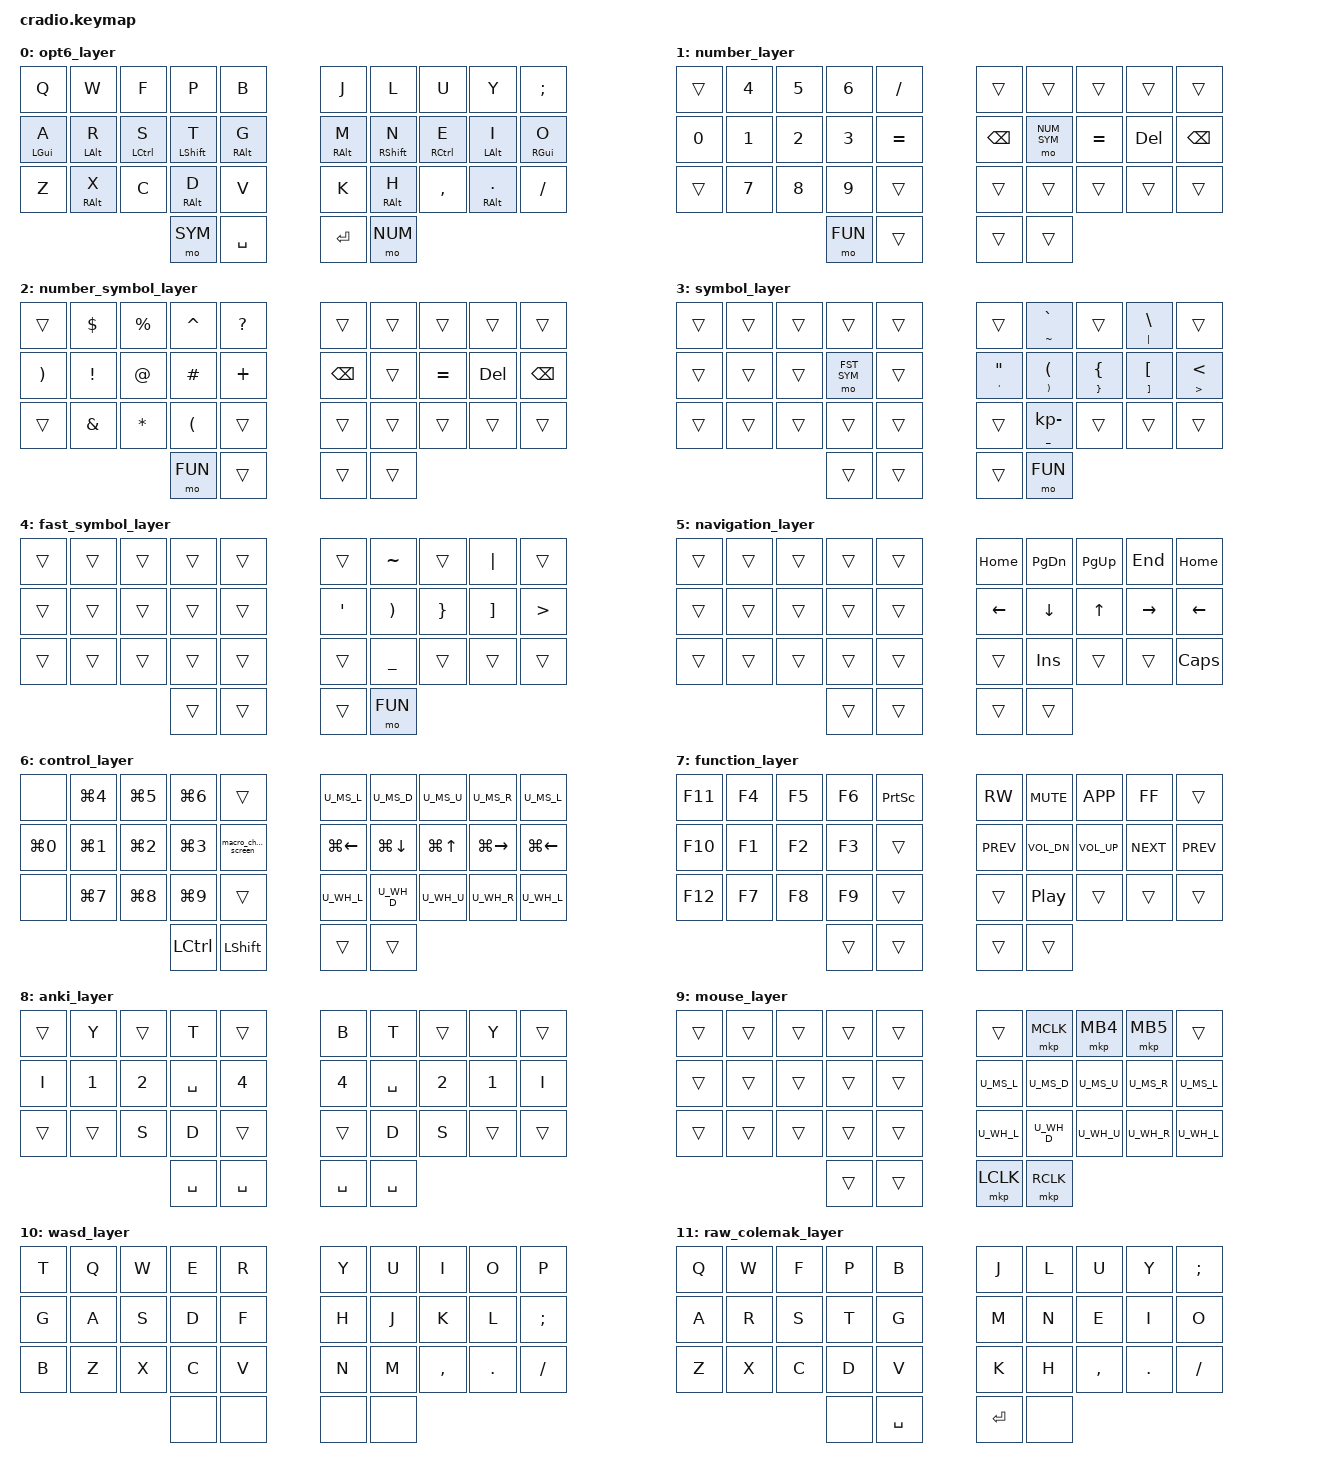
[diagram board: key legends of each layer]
/*
 * Copyright (c) 2020 The ZMK Contributors
 *
 * SPDX-License-Identifier: MIT
 */


// KEY NUMBERS
    // |    0    |    1    |    2    |    3    |     4   |        |     5   |     6   |    7    |    8    |    9    |
    // |   10    |   11    |   12    |   13    |    14   |        |    15   |    16   |   17    |   18    |   19    |
    // |   20    |   21    |   22    |   23    |    24   |        |    25   |    26   |   27    |   28    |   29    |
    //                               |   30    |    31   |        |    32   |    33   |

#include <behaviors.dtsi>
#include <dt-bindings/zmk/keys.h>
#include <dt-bindings/zmk/bt.h>
#include <dt-bindings/zmk/mouse.h>

// Layer definitions
#define DEF 0
#define NUM 1
#define NUM_SYM 2
#define SYM 3
#define FST_SYM 4
#define NAV 5
#define CTR 6
#define FUN 7
#define ANKI 8
#define MOUSELAYER 9
#define WASD 10
#define RAW_COLEMAK 11

// Combo timeout
#define COMBO_TIMEOUT 40

// Combo keys
#define COMBO_ESC 2 3
#define COMBO_TAB 13 14
#define COMBO_NAV 30 31
#define COMBO_CTR 32 33
#define COMBO_ANKI 25 26 27
#define COMBO_WASD 2 11 13
#define COMBO_RAW_COLEMAK 1 10 23
#define COMBO_MOUSELAYER 10 20
//#define COMBO_BT_CLR 0 10 20 9 19 29
//#define COMBO_BT_PRV 0 10 20 15
//#define COMBO_BT_NXT 0 10 20 18
#define COMBO_BT_CLR 0 4
#define COMBO_BT_PRV 0 14
#define COMBO_BT_NXT 0 24
#define COMBO_CUT 21 23
#define COMBO_COPY 21 22
#define COMBO_PASTE 22 23
#define COMBO_UNDO 1 2
#define COMBO_REDO 1 3

#define COMBO_ANKI_L 22 23 24
#define COMBO_ESC_R 7 8
#define COMBO_TAB_R 15 16
#define COMBO_CUT_R 26 28
#define COMBO_COPY_R 26 27
#define COMBO_PASTE_R 27 28
#define COMBO_UNDO_R 6 7
#define COMBO_REDO_R 6 8

#include "mouse.dtsi"

// Thumb keys
#define LEFT_THUMB_KEYS 30 31
#define RIGHT_THUMB_KEYS 32 33

// Halve keys
#define LEFT_SIDE_KEYS 0 1 2 3 4 10 11 12 13 14 20 21 22 23 24 LEFT_THUMB_KEYS
#define RIGHT_SIDE_KEYS 5 6 7 8 9 15 16 17 18 19 25 26 27 28 29 RIGHT_THUMB_KEYS


/ {
    behaviors {
        dk: dual_key {
            compatible = "zmk,behavior-hold-tap";
            label = "DUAL_KEY";
            #binding-cells = <2>;
            flavor = "tap-preferred";
            tapping-term-ms = <200>;
            quick-tap-ms = <0>;
            bindings = <&kp>, <&kp>;
        };

        lhm: left_homerow_mods {
            compatible = "zmk,behavior-hold-tap";
            #binding-cells = <2>;
            flavor = "balanced";
            tapping-term-ms = <250>;
            quick-tap-ms = <150>;
            hold-trigger-key-positions = <RIGHT_SIDE_KEYS LEFT_THUMB_KEYS>;
            hold-trigger-on-release;
            bindings = <&kp>, <&kp>;
        };

        rhm: right_homerow_mods {
            compatible = "zmk,behavior-hold-tap";
            #binding-cells = <2>;
            flavor = "balanced";
            tapping-term-ms = <250>;
            quick-tap-ms = <150>;
            hold-trigger-key-positions = <LEFT_SIDE_KEYS RIGHT_THUMB_KEYS>;
            hold-trigger-on-release;
            bindings = <&kp>, <&kp>;
        };
    };

    macros {
        macro_copy: macro_copy {
            label = "macro_copy";
            compatible = "zmk,behavior-macro";
            #binding-cells = <0>;
            bindings
                = <&macro_press &kp LCTRL>
                , <&macro_tap &kp C>
                , <&macro_release &kp LCTRL>
                ;
        };
        macro_paste: macro_paste {
            label = "macro_paste";
            compatible = "zmk,behavior-macro";
            #binding-cells = <0>;
            bindings
                = <&macro_press &kp LCTRL>
                , <&macro_tap &kp V>
                , <&macro_release &kp LCTRL>
                ;
        };
        macro_cut: macro_cut {
            label = "macro_cut";
            compatible = "zmk,behavior-macro";
            #binding-cells = <0>;
            bindings
                = <&macro_press &kp LCTRL>
                , <&macro_tap &kp X>
                , <&macro_release &kp LCTRL>
                ;
        };

        macro_undo: macro_undo {
            label = "macro_undo";
            compatible = "zmk,behavior-macro";
            #binding-cells = <0>;
            bindings
                = <&macro_press &kp LCTRL>
                , <&macro_tap &kp Z>
                , <&macro_release &kp LCTRL>
                ;
        };
        macro_redo: macro_redo {
            label = "macro_redo";
            compatible = "zmk,behavior-macro";
            #binding-cells = <0>;
            bindings
                = <&macro_press &kp LCTRL>
                , <&macro_tap &kp Y>
                , <&macro_release &kp LCTRL>
                ;
        };
        macro_change_screen: macro_change_screen {
            label = "macro_change_screen";
            compatible = "zmk,behavior-macro";
            #binding-cells = <0>;
            bindings
                = <&macro_press &kp LCTRL>
                , <&macro_press &kp LSHIFT>
                , <&macro_tap &kp LG(RIGHT)>
                , <&macro_release &kp LSHIFT>
                , <&macro_release &kp LCTRL>
                ;
        };
    };

    combos {
        compatible = "zmk,combos";

        combo_esc {
            timeout-ms = <COMBO_TIMEOUT>;
            key-positions = <COMBO_ESC>;
            bindings = <&kp ESC>;
        };
        
        combo_tab {
            timeout-ms = <COMBO_TIMEOUT>;
            key-positions = <COMBO_TAB>;
            bindings = <&kp TAB>;
        };

        combo_esc_r {
            timeout-ms = <COMBO_TIMEOUT>;
            key-positions = <COMBO_ESC_R>;
            bindings = <&kp ESC>;
        };
        
        combo_tab_r {
            timeout-ms = <COMBO_TIMEOUT>;
            key-positions = <COMBO_TAB_R>;
            bindings = <&kp TAB>;
        };

        combo_nav{
            timeout-ms = <COMBO_TIMEOUT>;
            key-positions = <COMBO_NAV>;
            bindings = <&mo NAV>;
        };

        combo_ctr{
            timeout-ms = <COMBO_TIMEOUT>;
            key-positions = <COMBO_CTR>;
            bindings = <&mo CTR>;
        };

        combo_anki{
            timeout-ms = <COMBO_TIMEOUT>;
            key-positions = <COMBO_ANKI>;
            bindings = <&tog ANKI>;
        };
        combo_mouselayer{
            timeout-ms = <COMBO_TIMEOUT>;
            key-positions = <COMBO_MOUSELAYER>;
            bindings = <&tog MOUSELAYER>;
        };
        combo_wasd{
            timeout-ms = <COMBO_TIMEOUT>;
            key-positions = <COMBO_WASD>;
            bindings = <&tog WASD>;
        };
        combo_raw_colemak{
            timeout-ms = <COMBO_TIMEOUT>;
            key-positions = <COMBO_RAW_COLEMAK>;
            bindings = <&tog RAW_COLEMAK>;
        };

        combo_anki_l{
            timeout-ms = <COMBO_TIMEOUT>;
            key-positions = <COMBO_ANKI_L>;
            bindings = <&tog ANKI>;
        };

        combo_bt_clr{
            timeout-ms = <COMBO_TIMEOUT>;
            key-positions = <COMBO_BT_CLR>;
            bindings = <&bt BT_CLR>;
        };

        combo_bt_prv{
            timeout-ms = <COMBO_TIMEOUT>;
            key-positions = <COMBO_BT_PRV>;
            bindings = <&bt BT_PRV>;
        };

        combo_bt_nxt{
            timeout-ms = <COMBO_TIMEOUT>;
            key-positions = <COMBO_BT_NXT>;
            bindings = <&bt BT_NXT>;
        };

        combo_cut {
            timeout-ms = <COMBO_TIMEOUT>;
            key-positions = <COMBO_CUT>;
            bindings = <&macro_cut>;
        };
        combo_copy {
            timeout-ms = <COMBO_TIMEOUT>;
            key-positions = <COMBO_COPY>;
            bindings = <&macro_copy>;
        };
        combo_paste {
            timeout-ms = <COMBO_TIMEOUT>;
            key-positions = <COMBO_PASTE>;
            bindings = <&macro_paste>;
        };

        combo_undo {
            timeout-ms = <COMBO_TIMEOUT>;
            key-positions = <COMBO_UNDO>;
            bindings = <&macro_undo>;
        };
        combo_redo {
            timeout-ms = <COMBO_TIMEOUT>;
            key-positions = <COMBO_REDO>;
            bindings = <&macro_redo>;
        };

        
        combo_cut_r {
            timeout-ms = <COMBO_TIMEOUT>;
            key-positions = <COMBO_CUT_R>;
            bindings = <&macro_cut>;
        };
        combo_copy_r {
            timeout-ms = <COMBO_TIMEOUT>;
            key-positions = <COMBO_COPY_R>;
            bindings = <&macro_copy>;
        };
        combo_paste_r {
            timeout-ms = <COMBO_TIMEOUT>;
            key-positions = <COMBO_PASTE_R>;
            bindings = <&macro_paste>;
        };

        combo_undo_r {
            timeout-ms = <COMBO_TIMEOUT>;
            key-positions = <COMBO_UNDO_R>;
            bindings = <&macro_undo>;
        };
        combo_redo_r {
            timeout-ms = <COMBO_TIMEOUT>;
            key-positions = <COMBO_REDO_R>;
            bindings = <&macro_redo>;
        };
    };

    keymap {
        compatible = "zmk,keymap";
            

    // colemakDH (default layer)
        // |    Q    |    W    |    F    |    P    |    B    |        |    J    |    L    |    U    |    Y    |    ;    |
        // |    A    |    R    |    S    |    T    |    G    |        |    M    |    N    |    E    |    I    |    O    |
        // |    Z    |    X    |    C    |    D    |    V    |        |    K    |    H    |    ,    |    .    |    /    |
        //                               |   SYM   |   SPC   |        |  ENTER  |   NUM   |

        opt6_layer {
            bindings = <
            &kp Q       &kp W       &kp F           &kp P           &kp B              &kp J       &kp L           &kp U           &kp Y             &kp SEMI
            &lhm LGUI A &lhm LALT R &lhm LCTRL S    &lhm LSHIFT T   &lhm RALT G        &rhm RALT M &rhm RSHIFT N   &rhm RCTRL E    &rhm LALT I       &rhm RGUI O
            &kp Z       &lhm RALT X &kp C           &lhm RALT D     &kp V              &kp K       &rhm RALT H     &kp COMMA       &rhm RALT DOT     &kp SLASH
                                                    &mo SYM         &kp SPC            &kp ENTER   &mo NUM
            >;
        };


    // number_layer
        // |         |    4    |    5    |    6    |    /    |        |         |         |         |         |         |
        // |    0    |    1    |    2    |    3    |    =    |        |  BSPC   | NUM_SYM |    =    |   DEL   |   BSPC  |
        // |         |    7    |    8    |    9    |         |        |         |         |         |         |         |
        //                               |   FUN   |   SPC   |        |  ENTER  | PRESSED |

        number_layer {
            bindings = <
            &trans      &kp NUM_4   &kp NUM_5   &kp NUM_6   &kp SLASH          &trans      &trans      &trans      &trans      &trans
            &kp NUM_0   &kp NUM_1   &kp NUM_2   &kp NUM_3   &kp EQUAL          &kp BSPC    &mo NUM_SYM &kp EQUAL   &kp DEL     &kp BSPC
            &trans      &kp NUM_7   &kp NUM_8   &kp NUM_9   &trans             &trans      &trans      &trans      &trans      &trans
                                                &mo FUN     &trans             &trans      &trans
            >;
        };


    // number_symbol_layer
        // |         |    $    |    %    |    ^    |    ?    |        |         |         |         |         |         |
        // |    )    |    !    |    @    |    #    |    +    |        |  BSPC   | PRESSED |    =    |   DEL   |   BSPC  |
        // |         |    &    |    *    |    (    |    _    |        |         |         |         |         |         |
        //                               |   FUN   |   SPC   |        |  ENTER  | PRESSED |

        number_symbol_layer {
            bindings = <
            &trans      &kp DOLLAR      &kp PERCENT         &kp CARET        &kp QMARK          &trans      &trans      &trans      &trans      &trans
            &kp RPAR    &kp EXCL        &kp AT              &kp HASH         &kp PLUS           &kp BSPC    &trans      &kp EQUAL   &kp DEL     &kp BSPC
            &trans      &kp AMPS        &kp ASTRK           &kp LPAR         &trans             &trans      &trans      &trans      &trans      &trans
                                        &mo FUN             &trans           &trans             &trans
            >;
        };


    // symbol_layer
        // |         |         |         |         |         |        |         |   ` ~   |         |   \ |   |         |
        // |         |         |         | FST_SYM |         |        |   " '   |   ( )   |   { }   |   [ ]   |   < >   |
        // |         |         |         |         |         |        |         |   - _   |         |         |         |
        //                               | PRESSED |   SPC   |        |  ENTER  |   FUN   | 

        symbol_layer {
            bindings = <
            &trans  &trans  &trans  &trans      &trans          &trans         &dk TILDE GRAVE     &trans          &dk PIPE BSLH   &trans
            &trans  &trans  &trans  &mo FST_SYM &trans          &dk APOS DQT   &dk RPAR LPAR       &dk RBRC LBRC   &dk RBKT LBKT   &dk GT LT
            &trans  &trans  &trans  &trans      &trans          &trans         &dk UNDER KP_MINUS  &trans          &trans          &trans
                                    &trans      &trans          &trans         &mo FUN
            >;
        };


    // fast_symbol_layer
        // |         |         |         |         |         |        |         |    ~    |         |    |    |         |
        // |         |         |         |         |         |        |    '    |    )    |    }    |    ]    |    >    |
        // |         |         |         |         |         |        |         |    _    |         |         |         |
        //                               | PRESSED |   SPC   |        |  ENTER  |   FUN   | 

        fast_symbol_layer {
            bindings = <
            &trans  &trans  &trans  &trans  &trans          &trans          &kp TILDE       &trans          &kp PIPE        &trans
            &trans  &trans  &trans  &trans  &trans          &kp APOS        &kp RPAR        &kp RBRC        &kp RBKT        &kp GT
            &trans  &trans  &trans  &trans  &trans          &trans          &kp UNDER       &trans          &trans          &trans
                                    &trans  &trans          &trans          &mo FUN
            >;
        };


    // navigation_layer
        // |         |         |         |         |         |        |   Home  | Pg down |  Pg up  |   End   |   Home  |
        // |         |         |         |         |         |        |    ←    |    ↓    |    ↑    |    →   |    ←   |
        // |         |         |         |         |         |        |         |   INS   |         |         |   Caps  |
        //                               |  COMBO  |  COMBO  |        |         |         |

        navigation_layer {
            bindings = <
            &trans  &trans  &trans  &trans  &trans          &kp HOME    &kp PG_DN   &kp PG_UP   &kp END     &kp HOME
            &trans  &trans  &trans  &trans  &trans          &kp LEFT    &kp DOWN    &kp UP      &kp RIGHT   &kp LEFT
            &trans  &trans  &trans  &trans  &trans          &trans      &kp INSERT  &trans      &trans      &kp CAPS
                                    &trans  &trans          &trans      &trans
            >;
        };


    // control_layer
        // Everything is gui modified
        // |         |    4    |    5    |    6    |         |        |    ←   |     ↓    |    ↑   |    →    |    ←    | // mouse
        // |    0    |    1    |    2    |    3    |         |        |    ←   |     ↓    |    ↑   |    →    |    ←    | // gui
        // |         |    7    |    8    |    9    |         |        |    ←   |     ↓    |    ↑   |    →    |    ←    | // wheel
        //                               |  SHIFT  |  lCtrl  |        |  COMBO  |   COMBO  |

        control_layer {
            bindings = <
            &none           &kp LG(NUM_4)   &kp LG(NUM_5)       &kp LG(NUM_6)       &trans                      U_MS_L            U_MS_D                U_MS_U          U_MS_R          U_MS_L
            &kp LG(NUM_0)   &kp LG(NUM_1)   &kp LG(NUM_2)       &kp LG(NUM_3)       &macro_change_screen        &kp LG(LEFT)      &kp LG(DOWN)          &kp LG(UP)      &kp LG(RIGHT)   &kp LG(LEFT)
            &none           &kp LG(NUM_7)   &kp LG(NUM_8)       &kp LG(NUM_9)       &trans                      U_WH_L            U_WH_D                U_WH_U          U_WH_R          U_WH_L
                                                                &kp LCTRL           &kp LSHIFT                  &trans            &trans
            >;
        };


    // function_layer
        // |   F11   |    F4   |    F5   |    F6   |  PrtScn |        |   C_RW  |  vol 1/0 |  K_APP |  C_FF   |         |
        // |   F10   |    F1   |    F2   |    F3   |         |        | med prev|   vol-   |   vol+ | med next| med prev|
        // |   F12   |    F7   |    F8   |    F9   |         |        |         | media p/p|        |         |         |
        //                               | PRESSED |         |        |         |  PRESSED |

        function_layer {
            bindings = <
            &kp F11 &kp F4  &kp F5  &kp F6  &kp PSCRN              &kp C_RW    &kp C_MUTE        &kp K_APP       &kp C_FF    &trans
            &kp F10 &kp F1  &kp F2  &kp F3  &trans                 &kp C_PREV  &kp C_VOL_DN      &kp C_VOL_UP    &kp C_NEXT  &kp C_PREV
            &kp F12 &kp F7  &kp F8  &kp F9  &trans                 &trans      &kp C_PLAY_PAUSE  &trans          &trans      &trans
                                    &trans  &trans                 &trans      &trans
            >;
        };


    // anki_layer
        // |&tog ANKI|    Y    |         |    T    |  K_REDO |        | K_REDO  |    T     |        |    Y    |         |
        // |    I    |    1    |    2    |  SPACE  |    4    |        |    4    |  SPACE   |    2   |    1    |    I    |
        // |         |    S    |    B    |    D    |  K_UNDO |        | K_UNDO  |    D     |    S   |         |         |
        //                               |  SPACE  |         |        |         |  SPACE   |

        anki_layer {
            bindings = <
            &trans     &kp Y      &trans     &kp T      &trans             &kp B         &kp T      &trans     &kp Y       &trans
            &kp I      &kp NUM_1  &kp NUM_2  &kp SPC    &kp NUM_4          &kp NUM_4     &kp SPC    &kp NUM_2  &kp NUM_1   &kp I
            &trans     &trans     &kp S      &kp D      &trans             &trans        &kp D      &kp S      &trans      &trans
                                             &kp SPC    &kp SPC            &kp SPC       &kp SPC
            >;
        };

    // mouse_layer
        // |         |         |         |         |         |        |         |    MMB   |   MB4  |   MB5   |         |
        // | TOGGLE  |         |         |         |         |        |    ←   |     ↓    |    ↑   |    →    |    ←    |  // move mouse
        // | TOGGLE  |         |         |         |         |        |    ←   |     ↓    |    ↑   |    →    |    ←    |  // scroll
        //                               |         |         |        |   LMB   |    RMB   |

        mouse_layer {
            bindings = <
            &trans    &trans      &trans     &trans        &trans                 &trans          &mkp MCLK     &mkp MB4    &mkp MB5    &trans
            &trans    &trans      &trans     &trans        &trans                 U_MS_L          U_MS_D        U_MS_U      U_MS_R      U_MS_L
            &trans    &trans      &trans     &trans        &trans                 U_WH_L          U_WH_D        U_WH_U      U_WH_R      U_WH_L
                                             &trans        &trans                 &mkp LCLK       &mkp RCLK
            >;
        };

    // wasd_layer
        // |    T    |    Q    |    W    |    E    |    R    |        |    Y    |    U    |    I    |    O    |    P    |
        // |    G    |    A    |    S    |    D    |    F    |        |    H    |    J    |    K    |    L    |    ;    |
        // |    B    |    Z    |    X    |    C    |    V    |        |    N    |    M    |    ,    |    .    |    /    |
        //                               |   SYM   |   SPC   |        |  ENTER  |   NUM   |

        wasd_layer {
            bindings = <
            &kp T       &kp Q       &kp W           &kp E           &kp R              &kp Y       &kp U           &kp I           &kp O             &kp P
            &kp G       &kp A       &kp S           &kp D           &kp F              &kp H       &kp J           &kp K           &kp L             &kp SEMI
            &kp B       &kp Z       &kp X           &kp C           &kp V              &kp N       &kp M           &kp COMMA       &kp DOT           &kp SLASH
                                                    &none           &none              &none       &none
            >;
        };

    // raw_colemak_layer
        // |    Q    |    W    |    F    |    P    |    B    |        |    J    |    L    |    U    |    Y    |    ;    |
        // |    A    |    R    |    S    |    T    |    G    |        |    M    |    N    |    E    |    I    |    O    |
        // |    Z    |    X    |    C    |    D    |    V    |        |    K    |    H    |    ,    |    .    |    /    |
        //                               |   SYM   |   SPC   |        |  ENTER  |   NUM   |

        raw_colemak_layer {
            bindings = <
            &kp Q       &kp W       &kp F           &kp P           &kp B              &kp J       &kp L           &kp U           &kp Y             &kp SEMI
            &kp A       &kp R       &kp S           &kp T           &kp G              &kp M       &kp N           &kp E           &kp I             &kp O
            &kp Z       &kp X       &kp C           &kp D           &kp V              &kp K       &kp H           &kp COMMA       &kp DOT           &kp SLASH
                                                    &none           &kp SPC            &kp ENTER   &none
            >;
        };

	};
};
